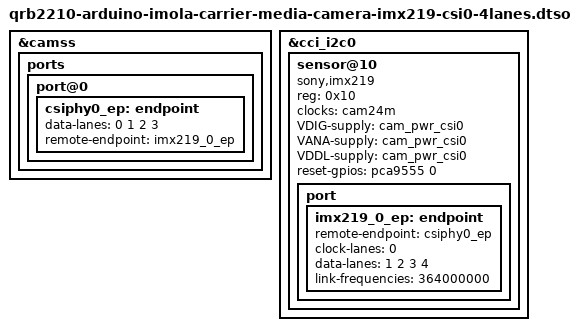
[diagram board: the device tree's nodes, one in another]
// SPDX-License-Identifier: (GPL-2.0+ OR BSD-3-Clause)
/*
 * Copyright (c) 2025, Arduino SA
 */

/dts-v1/;
/plugin/;

#include <dt-bindings/gpio/gpio.h>
#include "qrb2210-arduino-imola-carrier-media-common.dtsi"

&camss {
	ports {
		port@0 {
			csiphy0_ep: endpoint {
				data-lanes = <0 1 2 3>;
				remote-endpoint = <&imx219_0_ep>;
			};
		};
	};
};

&cci_i2c0 {
	#address-cells = <1>;
	#size-cells = <0>;

	sensor@10 {
		compatible = "sony,imx219";
		reg = <0x10>;
		clocks = <&cam24m>;
		status = "okay";

		VDIG-supply = <&cam_pwr_csi0>;
		VANA-supply = <&cam_pwr_csi0>;
		VDDL-supply = <&cam_pwr_csi0>;

		reset-gpios = <&pca9555 0 GPIO_ACTIVE_HIGH>;

		port {
			/* MIPI CSI-2 bus endpoint */
			imx219_0_ep: endpoint {
				remote-endpoint = <&csiphy0_ep>;
				clock-lanes = <0>;
				data-lanes = <1 2 3 4>;
				link-frequencies = /bits/ 64 <364000000>;
			};
		};
	};
};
